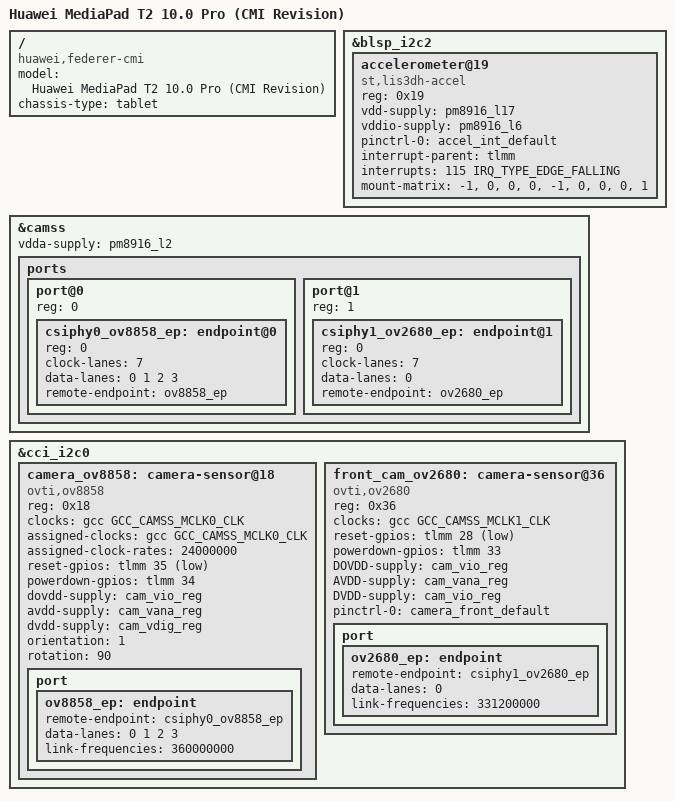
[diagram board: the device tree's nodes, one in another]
// SPDX-License-Identifier: GPL-2.0-only
/dts-v1/;

#include "msm8939-huawei-federer-common.dtsi"

/ {
	model = "Huawei MediaPad T2 10.0 Pro (CMI Revision)";
	compatible = "huawei,federer-cmi", "qcom,msm8939";
	chassis-type = "tablet";
};

&blsp_i2c2 {
	status = "okay";

	accelerometer@19 {
		compatible = "st,lis3dh-accel";
		reg = <0x19>;

		vdd-supply = <&pm8916_l17>;
		vddio-supply = <&pm8916_l6>;

		pinctrl-0 = <&accel_int_default>;
		pinctrl-names = "default";
		interrupt-parent = <&tlmm>;
		interrupts = <115 IRQ_TYPE_EDGE_FALLING>;

		mount-matrix =  "-1", "0", "0",
				"0", "-1", "0",
				"0", "0", "1";
	};
};

&camss {
	vdda-supply = <&pm8916_l2>;
	status = "okay";

	ports {
		port@0 {
			reg = <0>;
			#address-cells = <1>;
			#size-cells = <0>;

			/* csiphy0 steuert hier die OmniVision-Hauptkamera */
			csiphy0_ov8858_ep: endpoint@0 {
				reg = <0>;
				clock-lanes = <7>;
				data-lanes = <0 1 2 3>;
				remote-endpoint = <&ov8858_ep>;
			};
		};

		port@1 {
			reg = <1>;
			#address-cells = <1>;
			#size-cells = <0>;

			csiphy1_ov2680_ep: endpoint@1 {
				reg = <0>;
				clock-lanes = <7>;
				data-lanes = <0>;
				remote-endpoint = <&ov2680_ep>;
			};
		};
	};
};

&cci_i2c0 {
	camera_ov8858: camera-sensor@18 {
		compatible = "ovti,ov8858";
		reg = <0x18>;

		clocks = <&gcc GCC_CAMSS_MCLK0_CLK>;
		clock-names = "xvclk";
		assigned-clocks = <&gcc GCC_CAMSS_MCLK0_CLK>;
		assigned-clock-rates = <24000000>;

		reset-gpios = <&tlmm 35 GPIO_ACTIVE_LOW>;
		powerdown-gpios  = <&tlmm 34 GPIO_ACTIVE_HIGH>;

		dovdd-supply = <&cam_vio_reg>;
		avdd-supply = <&cam_vana_reg>;
		dvdd-supply = <&cam_vdig_reg>;

		//pinctrl-0 = <&camera_rear_default>;
		//pinctrl-names = "default";

		orientation = <1>;
		rotation = <90>;

		port {
			ov8858_ep: endpoint {
				remote-endpoint = <&csiphy0_ov8858_ep>;
				data-lanes = <0 1 2 3>;
				link-frequencies = /bits/ 64 <360000000>;
			};
		};
	};

	front_cam_ov2680: camera-sensor@36 {
		compatible = "ovti,ov2680";
		reg = <0x36>;
		clocks = <&gcc GCC_CAMSS_MCLK1_CLK>;
		clock-names = "xvclk";

		reset-gpios = <&tlmm 28 GPIO_ACTIVE_LOW>;
		powerdown-gpios = <&tlmm 33 GPIO_ACTIVE_HIGH>;

		DOVDD-supply = <&cam_vio_reg>;
		AVDD-supply = <&cam_vana_reg>;
		DVDD-supply = <&cam_vio_reg>;

		pinctrl-0 = <&camera_front_default>;
		pinctrl-names = "default";

		port {
			ov2680_ep: endpoint {
				remote-endpoint = <&csiphy1_ov2680_ep>;
				data-lanes = <0>;
				link-frequencies = /bits/ 64 <331200000>;
			};
		};
	};
};
